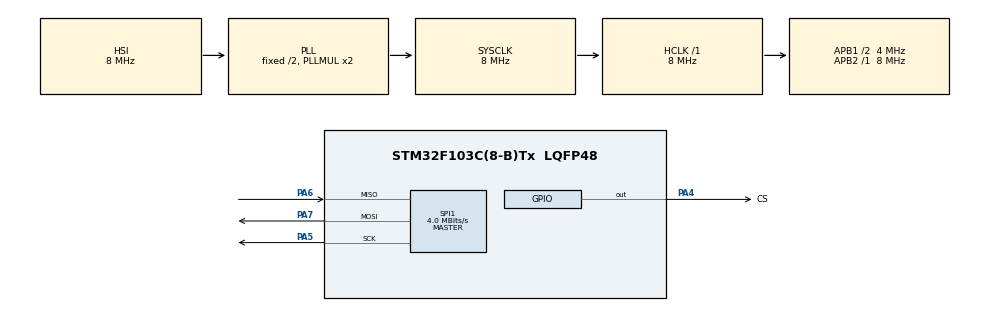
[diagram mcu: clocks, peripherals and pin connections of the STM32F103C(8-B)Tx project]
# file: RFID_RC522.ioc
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Mcu.Family=STM32F1
PA6.Mode=Full_Duplex_Master
PA7.Mode=Full_Duplex_Master
SPI1.VirtualType=VM_MASTER
RCC.APB1CLKDivider=RCC_HCLK_DIV2
RCC.SYSCLKSource=RCC_SYSCLKSOURCE_PLLCLK
ProjectManager.StackSize=0x400
PA13.Signal=SYS_JTMS-SWDIO
ProjectManager.TargetToolchain=MDK-ARM V5
SPI1.Direction=SPI_DIRECTION_2LINES
RCC.HCLKFreq_Value=8000000
RCC.APB2TimFreq_Value=8000000
SPI1.CalculateBaudRate=4.0 MBits/s
RCC.USBFreq_Value=8000000
RCC.AHBFreq_Value=8000000
PA5.Signal=SPI1_SCK
board=custom
RCC.APB2Freq_Value=8000000
SPI1.Mode=SPI_MODE_MASTER
PA14.Mode=Serial_Wire
PA13.Mode=Serial_Wire
Mcu.Name=STM32F103C(8-B)Tx
PA4.Signal=GPIO_Output
RCC.SYSCLKFreq_VALUE=8000000
Mcu.Package=LQFP48
PA6.Signal=SPI1_MISO
PA14.Signal=SYS_JTCK-SWCLK
ProjectManager.HeapSize=0x200
NVIC.PriorityGroup=NVIC_PRIORITYGROUP_4
RCC.APB1TimFreq_Value=8000000
RCC.APB1Freq_Value=4000000
SPI1.BaudRatePrescaler=SPI_BAUDRATEPRESCALER_2
PA4.GPIO_Label=CS
PA7.Signal=SPI1_MOSI
PA5.Mode=Full_Duplex_Master

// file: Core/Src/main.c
/* USER CODE BEGIN Header */
/**
  ******************************************************************************
  * @file           : main.c
  * @brief          : Main program body
  ******************************************************************************
  * @attention
  *
  * <h2><center>&copy; Copyright (c) 2020 STMicroelectronics.
  * All rights reserved.</center></h2>
  *
  * This software component is licensed by ST under BSD 3-Clause license,
  * the "License"; You may not use this file except in compliance with the
  * License. You may obtain a copy of the License at:
  *                        opensource.org/licenses/BSD-3-Clause
  *
  ******************************************************************************
  */
/* USER CODE END Header */
#include "main.h"

/* USER CODE BEGIN Includes */
#include "../../../lib/drivers/rfid/rc522/rc522.h"
/* USER CODE END Includes */

SPI_HandleTypeDef hspi1;

/* USER CODE BEGIN PV */
MFRC522_Device RFID1;
uint8_t CardID[5];
uint8_t MyID[5] = {0x43, 0xdc, 0x52, 0xb6, 0x7b};
uint8_t Status=0;
/* USER CODE END PV */

void SystemClock_Config(void);
static void MX_GPIO_Init(void);
static void MX_SPI1_Init(void);

int main(void)
{

  /* MCU Configuration--------------------------------------------------------*/

  /* Reset of all peripherals, Initializes the Flash interface and the Systick. */
  HAL_Init();

  /* Configure the system clock */
  SystemClock_Config();

  /* Initialize all configured peripherals */
  MX_GPIO_Init();
  MX_SPI1_Init();
  /* USER CODE BEGIN 2 */
	MFRC522_Init(&RFID1, &hspi1, CS_GPIO_Port, CS_Pin);
  /* USER CODE END 2 */

  /* Infinite loop */
  while (1)
  {

    /* USER CODE BEGIN 3 */
		HAL_Delay(100);
      Status = MFRC522_Request(&RFID1, PICC_REQALL, CardID);
      if (Status != MI_OK)
      {
	        continue;
      }
      Status = MFRC522_Anticoll(&RFID1, CardID);
      if (Status != MI_OK)
      {
        continue;
      }
  }
  /* USER CODE END 3 */
}

void SystemClock_Config(void)
{
  RCC_OscInitTypeDef RCC_OscInitStruct = {0};
  RCC_ClkInitTypeDef RCC_ClkInitStruct = {0};

  /** Initializes the RCC Oscillators according to the specified parameters
  * in the RCC_OscInitTypeDef structure.
  */
  RCC_OscInitStruct.OscillatorType = RCC_OSCILLATORTYPE_HSI;
  RCC_OscInitStruct.HSIState = RCC_HSI_ON;
  RCC_OscInitStruct.HSICalibrationValue = RCC_HSICALIBRATION_DEFAULT;
  RCC_OscInitStruct.PLL.PLLState = RCC_PLL_ON;
  RCC_OscInitStruct.PLL.PLLSource = RCC_PLLSOURCE_HSI_DIV2;
  RCC_OscInitStruct.PLL.PLLMUL = RCC_PLL_MUL2;
  if (HAL_RCC_OscConfig(&RCC_OscInitStruct) != HAL_OK)
  {
    Error_Handler();
  }
  /** Initializes the CPU, AHB and APB buses clocks
  */
  RCC_ClkInitStruct.ClockType = RCC_CLOCKTYPE_HCLK|RCC_CLOCKTYPE_SYSCLK
                              |RCC_CLOCKTYPE_PCLK1|RCC_CLOCKTYPE_PCLK2;
  RCC_ClkInitStruct.SYSCLKSource = RCC_SYSCLKSOURCE_PLLCLK;
  RCC_ClkInitStruct.AHBCLKDivider = RCC_SYSCLK_DIV1;
  RCC_ClkInitStruct.APB1CLKDivider = RCC_HCLK_DIV2;
  RCC_ClkInitStruct.APB2CLKDivider = RCC_HCLK_DIV1;

  if (HAL_RCC_ClockConfig(&RCC_ClkInitStruct, FLASH_LATENCY_0) != HAL_OK)
  {
    Error_Handler();
  }
}

static void MX_SPI1_Init(void)
{

  /* SPI1 parameter configuration*/
  hspi1.Instance = SPI1;
  hspi1.Init.Mode = SPI_MODE_MASTER;
  hspi1.Init.Direction = SPI_DIRECTION_2LINES;
  hspi1.Init.DataSize = SPI_DATASIZE_8BIT;
  hspi1.Init.CLKPolarity = SPI_POLARITY_LOW;
  hspi1.Init.CLKPhase = SPI_PHASE_1EDGE;
  hspi1.Init.NSS = SPI_NSS_SOFT;
  hspi1.Init.BaudRatePrescaler = SPI_BAUDRATEPRESCALER_2;
  hspi1.Init.FirstBit = SPI_FIRSTBIT_MSB;
  hspi1.Init.TIMode = SPI_TIMODE_DISABLE;
  hspi1.Init.CRCCalculation = SPI_CRCCALCULATION_DISABLE;
  hspi1.Init.CRCPolynomial = 10;
  if (HAL_SPI_Init(&hspi1) != HAL_OK)
  {
    Error_Handler();
  }

}

static void MX_GPIO_Init(void)
{
  GPIO_InitTypeDef GPIO_InitStruct = {0};

  /* GPIO Ports Clock Enable */
  __HAL_RCC_GPIOA_CLK_ENABLE();

  /*Configure GPIO pin Output Level */
  HAL_GPIO_WritePin(CS_GPIO_Port, CS_Pin, GPIO_PIN_RESET);

  /*Configure GPIO pin : CS_Pin */
  GPIO_InitStruct.Pin = CS_Pin;
  GPIO_InitStruct.Mode = GPIO_MODE_OUTPUT_PP;
  GPIO_InitStruct.Pull = GPIO_NOPULL;
  GPIO_InitStruct.Speed = GPIO_SPEED_FREQ_LOW;
  HAL_GPIO_Init(CS_GPIO_Port, &GPIO_InitStruct);

}

void Error_Handler(void)
{
}

/************************ (C) COPYRIGHT STMicroelectronics *****END OF FILE****/
